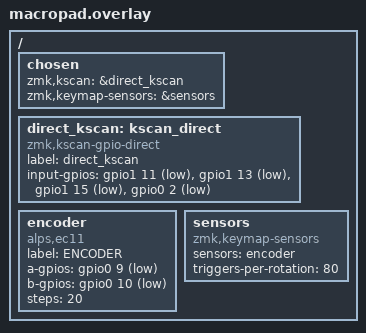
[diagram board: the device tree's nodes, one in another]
/ {
    chosen {
        zmk,kscan = &direct_kscan;
        zmk,keymap-sensors = &sensors;
    };
    direct_kscan: kscan_direct {
        compatible = "zmk,kscan-gpio-direct";
        label = "direct_kscan";
        input-gpios
            = <&gpio1 11 (GPIO_ACTIVE_LOW | GPIO_PULL_UP)>,
              <&gpio1 13 (GPIO_ACTIVE_LOW | GPIO_PULL_UP)>,
              <&gpio1 15 (GPIO_ACTIVE_LOW | GPIO_PULL_UP)>,
              <&gpio0 2 (GPIO_ACTIVE_LOW | GPIO_PULL_UP)>;
    };
    encoder: encoder {
        compatible = "alps,ec11";
        label = "ENCODER";
        a-gpios = <&gpio0 9 (GPIO_ACTIVE_LOW | GPIO_PULL_UP)>;
        b-gpios = <&gpio0 10 (GPIO_ACTIVE_LOW | GPIO_PULL_UP)>;
        steps = <20>;
        status = "okay";
    };
    sensors {
        compatible = "zmk,keymap-sensors";
        sensors = <&encoder>;
        triggers-per-rotation = <80>;
    };
};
